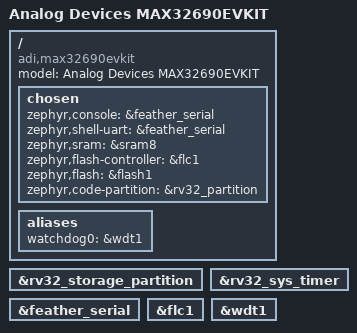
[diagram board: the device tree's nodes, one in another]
/*
 * Copyright (c) 2026 Analog Devices, Inc.
 *
 * SPDX-License-Identifier: Apache-2.0
 */

/dts-v1/;

#include <adi/max32/max32690-rv32.dtsi>
#include "max32690fthr.dtsi"

// #include <adi/max32/max32690-pinctrl.dtsi>
// #include <zephyr/dt-bindings/gpio/adi-max32-gpio.h>
// #include <zephyr/dt-bindings/memory-controller/adi-max32-hpb.h>
// #include <zephyr/dt-bindings/input/input-event-codes.h>
// #include <zephyr/dt-bindings/mipi_dbi/mipi_dbi.h>

/delete-node/ &storage_partition;

storage_partition: &rv32_storage_partition {};

/ {
	model = "Analog Devices MAX32690EVKIT";
	compatible = "adi,max32690evkit";

	chosen {
		zephyr,console = &feather_serial;
		zephyr,shell-uart = &feather_serial;
		zephyr,sram = &sram8;
		zephyr,flash-controller = &flc1;
		zephyr,flash = &flash1;
		zephyr,code-partition = &rv32_partition;
	};

	aliases {
		watchdog0 = &wdt1;
	};
};

&rv32_sys_timer {
	status = "okay";
};

&feather_serial {
	status = "okay";
};

&flc1 {
	status = "okay";
};

&wdt1 {
	status = "okay";
};
